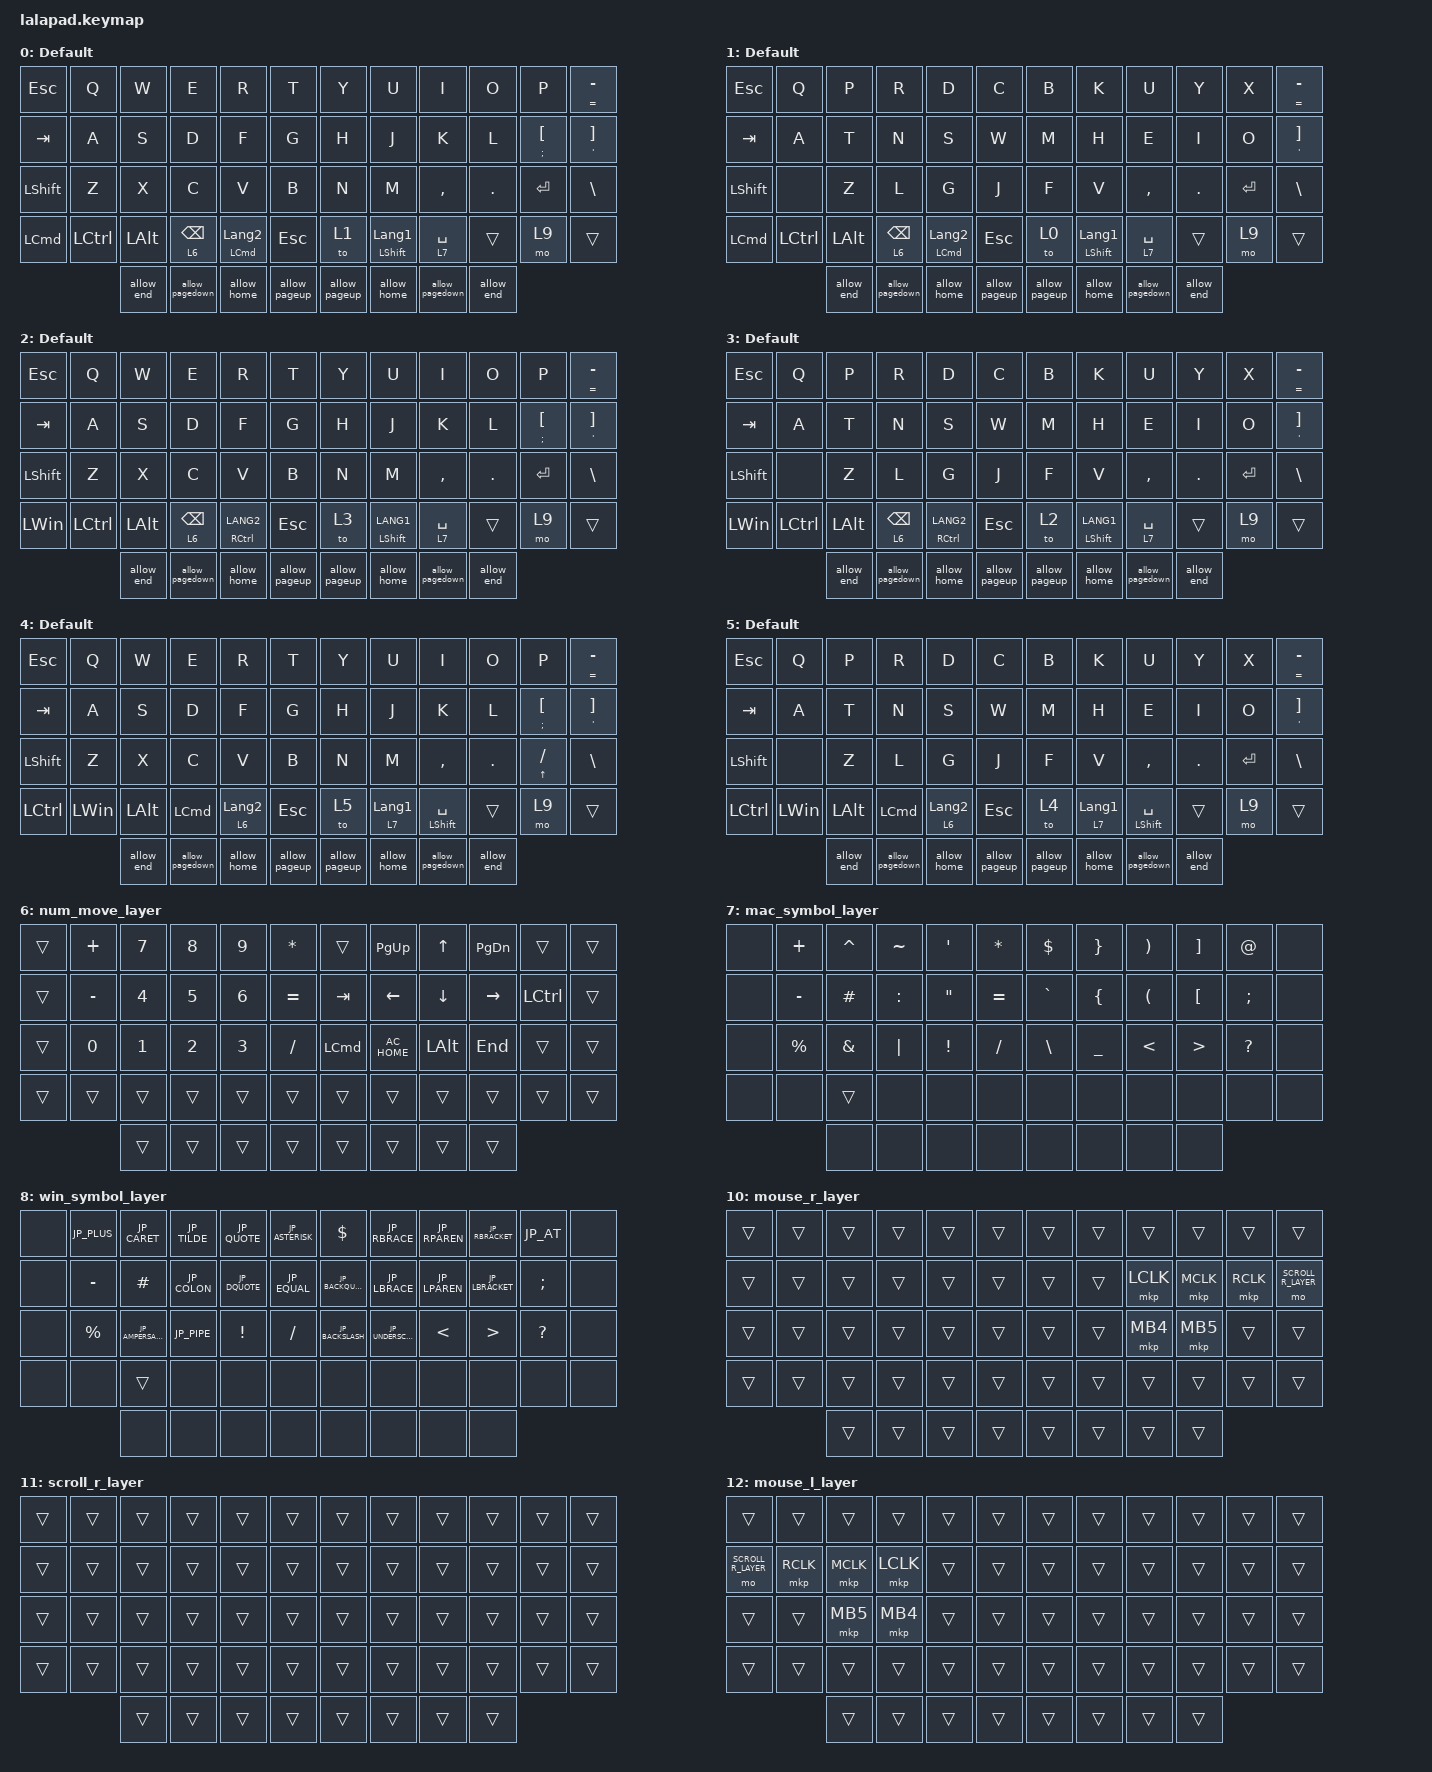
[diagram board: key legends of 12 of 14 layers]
#include <input/processors.dtsi>
#include <behaviors.dtsi>
#include <dt-bindings/zmk/bt.h>
#include <dt-bindings/zmk/keys.h>
#include <dt-bindings/zmk/outputs.h>
#include <dt-bindings/zmk/pointing.h>

#define DEFAULT_MAC_LAYER   0
#define UNIQUE_MAC_LAYER   1
#define DEFAULT_WINDOWS_LAYER   2
#define UNIQUE_WINDOWS_LAYER   3
#define DEFAULT_IOS_LAYER   4
#define UNIQUE_IOS_LAYER   5
#define NUM_MOVE_LAYER 6
#define MAC_SYMBOL_LAYER  7
#define WIN_SYMBOL_LAYER  8
#define SYSTEM_LAYER    9
#define MOUSE_R_LAYER   10
#define SCROLL_R_LAYER  11
#define MOUSE_L_LAYER   12
#define SCROLL_L_LAYER  13



// OS設定を日本語キーボードのまま使用するための変換定義
#define JP_DQUOTE       AT                // 
#define JP_AMPERSAND    CARET             // &
#define JP_QUOTE        AMPERSAND         // '
#define JP_EQUAL        UNDER             // =
#define JP_CARET        EQUAL             // ^
#define JP_YEN          0x89              // ¥
#define JP_PLUS         COLON             // +
#define JP_TILDE        PLUS              // ~
#define JP_PIPE         LS(0x89)          // |
#define JP_AT           LEFT_BRACKET      // @
#define JP_COLON        SINGLE_QUOTE      // :
#define JP_ASTERISK     DOUBLE_QUOTES     // *
#define JP_BACKQUOTE    LEFT_BRACE        // `
#define JP_UNDERSCORE   LS(0x87)          // _
#define JP_LBRACKET     RIGHT_BRACKET     // [
#define JP_RBRACKET     BACKSLASH         // ]
#define JP_LPAREN       ASTERISK          // (
#define JP_RPAREN       LEFT_PARENTHESIS  // )
#define JP_LBRACE       RIGHT_BRACE       // {
#define JP_RBRACE       PIPE              // }
#define JP_KANA         LANGUAGE_1        // かな
#define JP_EISU         LANGUAGE_2        // 英数
#define JP_HANZEN       GRAVE             // 半角/全角
#define JP_BACKSLASH    LS(0x57)          // \


// Mouse Scroll Value
// cirque trackpad input&layer control

&glidepoint_listener_R {
    input-processors =
        <&zip_xy_transform (INPUT_TRANSFORM_XY_SWAP | INPUT_TRANSFORM_X_INVERT | INPUT_TRANSFORM_Y_INVERT)>,
        <&zip_xy_scaler 3 2>,
        <&zip_temp_layer MOUSE_R_LAYER 500>;

    lowspeedmode {
        layers = <SYSTEM_LAYER>;
        input-processors =
            <&zip_xy_transform (INPUT_TRANSFORM_XY_SWAP | INPUT_TRANSFORM_X_INVERT | INPUT_TRANSFORM_Y_INVERT)>,
            <&zip_xy_scaler 3 5>,
            <&zip_temp_layer MOUSE_R_LAYER 500>;
    };

    scroller {
        layers = <SCROLL_R_LAYER>;
        input-processors =
            <&zip_xy_to_scroll_mapper>,
            <&zip_scroll_transform (INPUT_TRANSFORM_XY_SWAP | INPUT_TRANSFORM_Y_INVERT)>,
            <&zip_scroll_scaler 1 8>;
    };
};

&glidepoint_listener_L {
    input-processors =
        <&zip_xy_transform (INPUT_TRANSFORM_XY_SWAP | INPUT_TRANSFORM_X_INVERT | INPUT_TRANSFORM_Y_INVERT)>,
        <&zip_xy_scaler 3 2>,
        <&zip_temp_layer MOUSE_L_LAYER 500>;

//    lowspeedmode {
//        layers = <SYSTEM_LAYER>;
//        input-processors =
//            <&zip_xy_transform (INPUT_TRANSFORM_XY_SWAP | INPUT_TRANSFORM_X_INVERT | INPUT_TRANSFORM_Y_INVERT)>,
//            <&zip_xy_scaler 3 4>,
//            <&zip_temp_layer MOUSE_L_LAYER 500>;
//    };

    scroller {
        layers = <SCROLL_L_LAYER>;
        input-processors =
            <&zip_xy_to_scroll_mapper>,
            <&zip_scroll_transform (INPUT_TRANSFORM_XY_SWAP | INPUT_TRANSFORM_Y_INVERT)>,
            <&zip_scroll_scaler 1 6>;
    };
};

/ {
    behaviors {
        // Encoder to Mouse Scroll

        scroll_up_down: sensor_scroll_up_down {
            compatible = "zmk,behavior-sensor-rotate";
            #sensor-binding-cells = <0>;
            bindings = <&msc SCRL_UP>, <&msc SCRL_DOWN>;

            tap-ms = <20>;
            label = "SCROLL_UP_DOWN";
        };

        scroll_down_up: sensor_scroll_down_up {
            compatible = "zmk,behavior-sensor-rotate";
            #sensor-binding-cells = <0>;
            bindings = <&msc SCRL_DOWN>, <&msc SCRL_UP>;

            tap-ms = <20>;
            label = "SCROLL_DOWN_UP";
        };

        scroll_left_right: sensor_scroll_left_right {
            compatible = "zmk,behavior-sensor-rotate";
            #sensor-binding-cells = <0>;
            bindings = <&msc SCRL_LEFT>, <&msc SCRL_RIGHT>;

            tap-ms = <20>;
            label = "SCROLL_LEFT_RIGHT";
        };

        scroll_right_left: sensor_scroll_right_left {
            compatible = "zmk,behavior-sensor-rotate";
            #sensor-binding-cells = <0>;
            bindings = <&msc SCRL_RIGHT>, <&msc SCRL_LEFT>;

            tap-ms = <20>;
            label = "SCROLL_RIGHT_LEFT";
        };

        volume_up_down: sensor_volume_up_down {
            compatible = "zmk,behavior-sensor-rotate";
            #sensor-binding-cells = <0>;
            bindings = <&kp C_VOLUME_UP>, <&kp C_VOLUME_DOWN>;

            tap-ms = <20>;
            label = "VOLUME_UP_DOWN";
        };

        dot_comma: dot_comma {
            compatible = "zmk,behavior-mod-morph";
            #binding-cells = <0>;
            bindings = <&kp KP_DOT>, <&kp COMMA>;

            mods = <(MOD_LSFT|MOD_RSFT)>;
            label = "DOT_COMMA";
        };

        pls_minus: pls_minus {
            compatible = "zmk,behavior-mod-morph";
            #binding-cells = <0>;
            bindings = <&kp PLUS>, <&kp MINUS>;

            mods = <(MOD_LSFT|MOD_RSFT)>;
            label = "PLS_MINUS";
        };

        allow_pageup: allow_pageup {
            compatible = "zmk,behavior-mod-morph";
            #binding-cells = <0>;
            bindings = <&kp UP>, <&kp PAGE_UP>;

            mods = <(MOD_LCTL|MOD_RCTL)>;
            label = "ALLOW_PAGEUP";
        };

        allow_pagedown: allow_pagedown {
            compatible = "zmk,behavior-mod-morph";
            #binding-cells = <0>;
            bindings = <&kp DOWN>, <&kp PAGE_DOWN>;

            mods = <(MOD_LCTL|MOD_RCTL)>;
            label = "ALLOW_PAGEDOWN";
        };

        allow_home: allow_home {
            compatible = "zmk,behavior-mod-morph";
            #binding-cells = <0>;
            bindings = <&kp LEFT>, <&kp HOME>;

            mods = <(MOD_LCTL|MOD_RCTL)>;
            label = "ALLOW_HOME";
        };

        allow_end: allow_end {
            compatible = "zmk,behavior-mod-morph";
            #binding-cells = <0>;
            bindings = <&kp RIGHT>, <&kp END>;

            mods = <(MOD_LCTL|MOD_RCTL)>;
            label = "ALLOW_END";
        };

        mt2: mod_tap2 {
            compatible = "zmk,behavior-hold-tap";
            #binding-cells = <2>;
            flavor = "tap-preferred";
            tapping-term-ms = <200>;
            quick-tap-ms = <200>;
            require-prior-idle-ms = <125>;
            bindings = <&kp>, <&kp>;
        };

        ////////////////////
        //Changed to allow toggle layers to be specified as ON/OFF

        tog_on: toggle_layer_on_only {
            compatible = "zmk,behavior-toggle-layer";
            #binding-cells = <1>;
            display-name = "Toggle Layer On";
            toggle-mode = "on";
        };

        tog_off: toggle_layer_off_only {
            compatible = "zmk,behavior-toggle-layer";
            #binding-cells = <1>;
            display-name = "Toggle Layer Off";
            toggle-mode = "off";
        };

        ////////////////////
    };

    macros {
        Mac_bt: Mac_bt {
            compatible = "zmk,behavior-macro";
            #binding-cells = <0>;
            bindings =
                <&tog_off 0 &tog_off 1 &tog_off 2 &tog_off 3 &tog_off 4 &tog_off 5>,
                <&macro_wait_time 200>,
                <&bt BT_SEL 0>,
                <&macro_wait_time 400>;

            label = "MAC_BT";
        };

        Win_bt: WIN_bt {
            compatible = "zmk,behavior-macro";
            #binding-cells = <0>;
            bindings =
                <&tog_off 0 &tog_off 1 &tog_off 2 &tog_off 3 &tog_off 4 &tog_off 5>,
                <&macro_wait_time 200>,
                <&bt BT_SEL 3>,
                <&macro_wait_time 400>,
                <&tog_on 2>;

            label = "WIN_BT";
        };

        iPm_bt: ios_bt {
            compatible = "zmk,behavior-macro";
            #binding-cells = <0>;
            bindings =
                <&tog_off 0 &tog_off 1 &tog_off 2 &tog_off 3 &tog_off 4 &tog_off 5>,
                <&macro_wait_time 200>,
                <&bt BT_SEL 1>,
                <&macro_wait_time 400>,
                <&tog_on 4>;

            label = "IOS_BT";
        };

        iPh_bt: iPh_bt {
            compatible = "zmk,behavior-macro";
            #binding-cells = <0>;
            bindings =
                <&tog_off 0 &tog_off 1 &tog_off 2 &tog_off 3 &tog_off 4 &tog_off 5>,
                <&macro_wait_time 200>,
                <&bt BT_SEL 2>,
                <&macro_wait_time 400>,
                <&tog_on 4>;

            label = "IPH_BT";
        };
    };

    keymap {
        compatible = "zmk,keymap";

        DEFAULT_MAC_LAYER {
            display-name = "Default";
            sensor-bindings =
                <&inc_dec_kp C_BRIGHTNESS_INC C_BRI_DEC>,
                <&volume_up_down>;

            bindings = <
&kp ESC           &kp Q             &kp W         &kp E            &kp R                        &kp T          &kp Y          &kp U                      &kp I            &kp O       &kp P           &mt EQUAL MINUS
&kp TAB           &kp A             &kp S         &kp D            &kp F                        &kp G          &kp H          &kp J                      &kp K            &kp L       &mt2 SEMI LBKT  &mt2 SQT RBKT
&kp LSHFT         &kp Z             &kp X         &kp C            &kp V                        &kp B          &kp N          &kp M                      &kp COMMA        &kp PERIOD  &kp ENTER       &kp BSLH
&kp LEFT_COMMAND  &kp LEFT_CONTROL  &kp LEFT_ALT  &lt 6 BACKSPACE  &mt LEFT_COMMAND LANGUAGE_2  &kp ESCAPE     &to 1          &mt LEFT_SHIFT LANGUAGE_1  &lt 7 SPACE      &trans      &mo 9           &trans
                                    &allow_end    &allow_pagedown  &allow_home                  &allow_pageup  &allow_pageup  &allow_home                &allow_pagedown  &allow_end
            >;
        };

        UNIQUE_MAC_LAYER {
            display-name = "Default";
            sensor-bindings =
                <&inc_dec_kp C_BRIGHTNESS_INC C_BRIGHTNESS_DEC>,
                <&volume_up_down>;

            bindings = <
&kp ESC           &kp Q             &kp P         &kp R            &kp D                        &kp C          &kp B          &kp K                      &kp U            &kp Y       &kp X      &mt EQUAL MINUS
&kp TAB           &kp A             &kp T         &kp N            &kp S                        &kp W          &kp M          &kp H                      &kp E            &kp I       &kp O      &mt2 SQT RBKT
&kp LSHFT         &none             &kp Z         &kp L            &kp G                        &kp J          &kp F          &kp V                      &kp COMMA        &kp PERIOD  &kp ENTER  &kp BSLH
&kp LEFT_COMMAND  &kp LEFT_CONTROL  &kp LEFT_ALT  &lt 6 BACKSPACE  &mt LEFT_COMMAND LANGUAGE_2  &kp ESCAPE     &to 0          &mt LEFT_SHIFT LANGUAGE_1  &lt 7 SPACE      &trans      &mo 9      &trans
                                    &allow_end    &allow_pagedown  &allow_home                  &allow_pageup  &allow_pageup  &allow_home                &allow_pagedown  &allow_end
            >;
        };

        DEFAULT_WINDOWS_LAYER {
            display-name = "Default";
            sensor-bindings =
                <&inc_dec_kp C_BRIGHTNESS_INC C_BRI_DEC>,
                <&volume_up_down>;

            bindings = <
&kp ESC    &kp Q         &kp W         &kp E            &kp R                        &kp T          &kp Y          &kp U                      &kp I            &kp O       &kp P           &mt EQUAL MINUS
&kp TAB    &kp A         &kp S         &kp D            &kp F                        &kp G          &kp H          &kp J                      &kp K            &kp L       &mt2 SEMI LBKT  &mt2 SQT RBKT
&kp LSHFT  &kp Z         &kp X         &kp C            &kp V                        &kp B          &kp N          &kp M                      &kp COMMA        &kp PERIOD  &kp ENTER       &kp BSLH
&kp LEFT_WIN  &kp LCTRL  &kp LEFT_ALT  &lt 6 BACKSPACE  &mt RCTRL LANG2  &kp ESCAPE     &to 3          &mt LEFT_SHIFT  LANG1  &lt 7 SPACE      &trans      &mo 9           &trans
                         &allow_end    &allow_pagedown  &allow_home                  &allow_pageup  &allow_pageup  &allow_home                &allow_pagedown  &allow_end
            >;
        };

        UNIQUE_WINDOWS_LAYER {
            display-name = "Default";
            sensor-bindings =
                <&inc_dec_kp C_BRIGHTNESS_INC C_BRI_DEC>,
                <&volume_up_down>;

            bindings = <
&kp ESC    &kp Q         &kp P         &kp R            &kp D                        &kp C          &kp B          &kp K                      &kp U            &kp Y       &kp X      &mt EQUAL MINUS
&kp TAB    &kp A         &kp T         &kp N            &kp S                        &kp W          &kp M          &kp H                      &kp E            &kp I       &kp O      &mt2 SQT RBKT
&kp LSHFT  &none         &kp Z         &kp L            &kp G                        &kp J          &kp F          &kp V                      &kp COMMA        &kp PERIOD  &kp ENTER  &kp BSLH
&kp LEFT_WIN  &kp LCTRL  &kp LEFT_ALT  &lt 6 BACKSPACE  &mt RCTRL LANG2  &kp ESCAPE     &to 2          &mt LEFT_SHIFT LANG1  &lt 7 SPACE      &trans      &mo 9      &trans
                         &allow_end    &allow_pagedown  &allow_home                  &allow_pageup  &allow_pageup  &allow_home                &allow_pagedown  &allow_end
            >;
        };

        DEFAULT_IOS_LAYER {
            display-name = "Default";
            sensor-bindings = <&scroll_down_up>, <&scroll_up_down>;

            bindings = <
&kp ESC    &kp Q         &kp W         &kp E             &kp R                           &kp T          &kp Y          &kp U             &kp I                 &kp O       &kp P           &mt EQUAL MINUS
&kp TAB    &kp A         &kp S         &kp D             &kp F                           &kp G          &kp H          &kp J             &kp K                 &kp L       &mt2 SEMI LBKT  &mt2 SQT RBKT
&kp LSHFT  &kp Z         &kp X         &kp C             &kp V                           &kp B          &kp N          &kp M             &kp COMMA             &kp PERIOD  &mt2 UP SLASH   &kp BSLH
&kp LCTRL  &kp LEFT_WIN  &kp LEFT_ALT  &kp LEFT_COMMAND  &lt 6 LANGUAGE_2  &kp ESCAPE     &to 5          &lt 7 LANGUAGE_1  &mt LEFT_SHIFT SPACE  &trans      &mo 9           &trans
                         &allow_end    &allow_pagedown   &allow_home                     &allow_pageup  &allow_pageup  &allow_home       &allow_pagedown       &allow_end
            >;
        };

        UNIQUE_IOS_LAYER {
            display-name = "Default";
            sensor-bindings = <&scroll_down_up>, <&scroll_up_down>;

            bindings = <
&kp ESC    &kp Q         &kp P         &kp R             &kp D                           &kp C          &kp B          &kp K             &kp U                 &kp Y       &kp X      &mt EQUAL MINUS
&kp TAB    &kp A         &kp T         &kp N             &kp S                           &kp W          &kp M          &kp H             &kp E                 &kp I       &kp O      &mt2 SQT RBKT
&kp LSHFT  &none         &kp Z         &kp L             &kp G                           &kp J          &kp F          &kp V             &kp COMMA             &kp PERIOD  &kp ENTER  &kp BSLH
&kp LCTRL  &kp LEFT_WIN  &kp LEFT_ALT  &kp LEFT_COMMAND  &lt 6 LANGUAGE_2  &kp ESCAPE     &to 4          &lt 7 LANGUAGE_1  &mt LEFT_SHIFT SPACE  &trans      &mo 9      &trans
                         &allow_end    &allow_pagedown   &allow_home                     &allow_pageup  &allow_pageup  &allow_home       &allow_pagedown       &allow_end
            >;
        };

        NUM_MOVE_LAYER {
            display-name = "num_move_layer";
            sensor-bindings = <&scroll_left_right>, <&volume_up_down>;

            bindings = <
&trans  &kp PLUS      &kp NUMBER_7  &kp NUMBER_8  &kp NUMBER_9  &kp ASTERISK  &trans            &kp PAGE_UP     &kp UP_ARROW    &kp PAGE_DOWN    &trans            &trans
&trans  &kp MINUS     &kp NUMBER_4  &kp NUMBER_5  &kp NUMBER_6  &kp EQUAL     &kp TAB           &kp LEFT_ARROW  &kp DOWN_ARROW  &kp RIGHT_ARROW  &kp LEFT_CONTROL  &trans
&trans  &kp NUMBER_0  &kp NUMBER_1  &kp NUMBER_2  &kp NUMBER_3  &kp SLASH     &kp LEFT_COMMAND  &kp C_AC_HOME   &kp LEFT_ALT    &kp END          &trans            &trans
&trans  &trans        &trans        &trans        &trans        &trans        &trans            &trans          &trans          &trans           &trans            &trans
                      &trans        &trans        &trans        &trans        &trans            &trans          &trans          &trans
            >;
        };

        MAC_SYMBOL_LAYER {
            display-name = "mac_symbol_layer";
            bindings = <
&none  &kp PLUS     &kp CARET      &kp TILDE  &kp SINGLE_QUOTE   &kp ASTERISK  &kp DOLLAR     &kp RIGHT_BRACE  &kp RIGHT_PARENTHESIS  &kp RIGHT_BRACKET  &kp AT_SIGN    &none
&none  &kp MINUS    &kp HASH       &kp COLON  &kp DOUBLE_QUOTES  &kp EQUAL     &kp GRAVE      &kp LEFT_BRACE   &kp LEFT_PARENTHESIS   &kp LEFT_BRACKET   &kp SEMICOLON  &none
&none  &kp PERCENT  &kp AMPERSAND  &kp PIPE   &kp EXCLAMATION    &kp SLASH     &kp BACKSLASH  &kp UNDERSCORE   &kp LESS_THAN          &kp GREATER_THAN   &kp QUESTION   &none
&none  &none        &trans         &none      &none              &none         &none          &none            &none                  &none              &none          &none
                    &none          &none      &none              &none         &none          &none            &none                  &none
            >;

            sensor-bindings = <&scroll_down_up>, <&volume_up_down>;
        };

        WIN_SYMBOL_LAYER {
            display-name = "win_symbol_layer";
            bindings = <
&none  &kp JP_PLUS  &kp JP_CARET      &kp JP_TILDE  &kp JP_QUOTE     &kp JP_ASTERISK  &kp DOLLAR        &kp JP_RBRACE      &kp JP_RPAREN  &kp JP_RBRACKET   &kp JP_AT      &none
&none  &kp MINUS    &kp HASH          &kp JP_COLON  &kp JP_DQUOTE    &kp JP_EQUAL     &kp JP_BACKQUOTE  &kp JP_LBRACE      &kp JP_LPAREN  &kp JP_LBRACKET   &kp SEMICOLON  &none
&none  &kp PERCENT  &kp JP_AMPERSAND  &kp JP_PIPE   &kp EXCLAMATION  &kp SLASH        &kp JP_BACKSLASH  &kp JP_UNDERSCORE  &kp LESS_THAN  &kp GREATER_THAN  &kp QUESTION   &none
&none  &none        &trans            &none         &none            &none            &none             &none              &none          &none             &none          &none
                    &none             &none         &none            &none            &none             &none              &none          &none
            >;

            sensor-bindings = <&scroll_down_up>, <&volume_up_down>;
        };

        SYSTEM_LAYER {
            display-name = "system_layer";
            sensor-bindings =
                <&inc_dec_kp C_BRIGHTNESS_INC C_BRIGHTNESS_DEC>,
                <&volume_up_down>;

            bindings = <
&trans  &kp C_PREVIOUS    &kp C_VOLUME_UP    &kp C_BRIGHTNESS_INC  &trans  &trans  &out OUT_TOG      &kp PAGE_UP     &kp UP_ARROW  &kp PAGE_DOWN  &kp LS(LC(LG(NUMBER_4)))  &Mac_bt
&trans  &kp C_NEXT        &kp C_VOLUME_DOWN  &kp C_BRIGHTNESS_DEC  &trans  &trans  &kp TAB           &kp LEFT_ARROW  &kp DOWN      &kp RIGHT      &kp C_AC_PASTE            &iPm_bt
&trans  &kp C_PLAY_PAUSE  &kp C_MUTE         &trans                &trans  &trans  &kp LEFT_COMMAND  &mkp LCLK       &kp LEFT_ALT  &mkp RCLK      &trans                    &iPh_bt
&trans  &trans            &trans             &trans                &trans  &trans  &kp ESCAPE        &trans          &trans        &trans         &trans                    &Win_bt
                          &trans             &trans                &trans  &trans  &trans            &trans          &trans        &trans
            >;
        };

        MOUSE_R_LAYER {
            display-name = "mouse_r_layer";
            bindings = <
&trans  &trans  &trans  &trans  &trans  &trans  &trans  &trans  &trans     &trans     &trans     &trans
&trans  &trans  &trans  &trans  &trans  &trans  &trans  &trans  &mkp LCLK  &mkp MCLK  &mkp RCLK  &mo SCROLL_R_LAYER
&trans  &trans  &trans  &trans  &trans  &trans  &trans  &trans  &mkp MB4   &mkp MB5   &trans     &trans
&trans  &trans  &trans  &trans  &trans  &trans  &trans  &trans  &trans     &trans     &trans     &trans
                &trans  &trans  &trans  &trans  &trans  &trans  &trans     &trans
            >;
        };

        SCROLL_R_LAYER {
            display-name = "scroll_r_layer";
            bindings = <
&trans  &trans  &trans  &trans  &trans  &trans  &trans  &trans  &trans  &trans  &trans  &trans
&trans  &trans  &trans  &trans  &trans  &trans  &trans  &trans  &trans  &trans  &trans  &trans
&trans  &trans  &trans  &trans  &trans  &trans  &trans  &trans  &trans  &trans  &trans  &trans
&trans  &trans  &trans  &trans  &trans  &trans  &trans  &trans  &trans  &trans  &trans  &trans
                &trans  &trans  &trans  &trans  &trans  &trans  &trans  &trans
            >;
        };

        MOUSE_L_LAYER {
            display-name = "mouse_l_layer";
            bindings = <
&trans              &trans     &trans     &trans     &trans  &trans  &trans  &trans  &trans  &trans  &trans  &trans
&mo SCROLL_R_LAYER  &mkp RCLK  &mkp MCLK  &mkp LCLK  &trans  &trans  &trans  &trans  &trans  &trans  &trans  &trans
&trans              &trans     &mkp MB5   &mkp MB4   &trans  &trans  &trans  &trans  &trans  &trans  &trans  &trans
&trans              &trans     &trans     &trans     &trans  &trans  &trans  &trans  &trans  &trans  &trans  &trans
                               &trans     &trans     &trans  &trans  &trans  &trans  &trans  &trans
            >;
        };

        SCROLL_L_LAYER {
            display-name = "scroll_l_layer";
            bindings = <
&trans  &trans  &trans  &trans  &trans  &trans  &trans  &trans  &trans  &trans  &trans  &trans
&trans  &trans  &trans  &trans  &trans  &trans  &trans  &trans  &trans  &trans  &trans  &trans
&trans  &trans  &trans  &trans  &trans  &trans  &trans  &trans  &trans  &trans  &trans  &trans
&trans  &trans  &trans  &trans  &trans  &trans  &trans  &trans  &trans  &trans  &trans  &trans
                &trans  &trans  &trans  &trans  &trans  &trans  &trans  &trans
            >;
        };
    };
};
